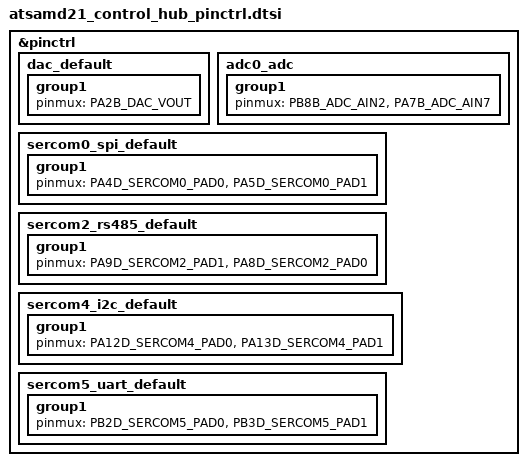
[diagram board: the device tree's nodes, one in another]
/*
 * Copyright (c) 2022, Gerson Fernando Budke <nandojve@gmail.com>
 * SPDX-License-Identifier: Apache-2.0
 */

#include <dt-bindings/pinctrl/samd21-da1gXabcd-pinctrl.h>

&pinctrl {
	dac_default: dac_default {
		group1 {
			pinmux = <PA2B_DAC_VOUT>;
		};
	};

	adc0_adc: adc0_adc {
		group1 {
			pinmux = <PB8B_ADC_AIN2>, <PA7B_ADC_AIN7>; 
		};
	};

	sercom0_spi_default: sercom0_spi_default {
		group1 {
			pinmux = <PA4D_SERCOM0_PAD0>,
				 <PA5D_SERCOM0_PAD1>;
				//  <PA7D_SERCOM0_PAD3>;
		};
	};

	sercom2_rs485_default: sercom2_rs485_default {
		group1 {
			pinmux = <PA9D_SERCOM2_PAD1>,
				 <PA8D_SERCOM2_PAD0>;
		};
	};

	sercom4_i2c_default: sercom4_i2c_default {
		group1 {
			pinmux = <PA12D_SERCOM4_PAD0>,
				 <PA13D_SERCOM4_PAD1>;
		};
	};

	sercom5_uart_default: sercom5_uart_default {
		group1 {
			pinmux = <PB2D_SERCOM5_PAD0>,
				 <PB3D_SERCOM5_PAD1>;
		};
	};
};
